# M440 register map
File version: 0.1
Registers are 32-bit, read-write, reset 0x0 unless marked. A register's access mark holds for its fields unless they carry their own. Offsets are from the block's base; [hi:lo] are bit positions; {n}, {i} and the like mark numbered series.

## WD — Watchdog Timer (WD)
Base 0x400F2000
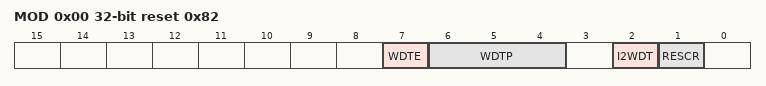
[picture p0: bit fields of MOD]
0x00 MOD reset 0x82 — WD Mode Register
  [7] WDTE, [6:4] WDTP, [2] I2WDT, [1] RESCR
0x04 CR wo (reset mask 0xFFFFFF00) — WD Control Register
  [7:0] WDCR

## CG — Clock Generator (CG)
Base 0x400F3000
0x00 SYSCR reset 0x10000 — System Control Register
  [21] PSCSTOP, [20] FCSTOP2, [18] FCSTOP1, [17] FCSTOP0, [17:16] SCOSEL, [13] FPSEL1 ro, [12] FPSEL0, [10:8] PRCK, [2:0] GEAR
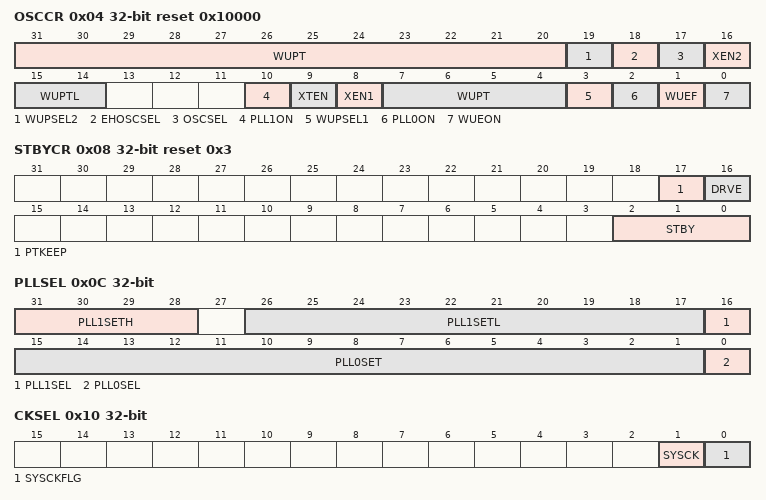
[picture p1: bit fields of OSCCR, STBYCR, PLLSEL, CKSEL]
0x04 OSCCR reset 0x10000 — Oscillation Control Register
  [31:20] WUPT, [19] WUPSEL2, [18] EHOSCSEL, [17] OSCSEL, [16] XEN2, [15:14] WUPTL, [10] PLL1ON, [9] XTEN, [8] XEN1, [7:4] WUPT ro, [3] WUPSEL1, [2] PLL0ON, [1] WUEF ro, [0] WUEON wo
0x08 STBYCR reset 0x3 — Standby Control Register
  [17] PTKEEP, [16] DRVE, [2:0] STBY
0x0C PLLSEL — PLL Selection Register
  [31:28] PLL1SETH, [26:17] PLL1SETL, [16] PLL1SEL, [15:1] PLL0SET, [0] PLL0SEL
0x10 CKSEL — System Clock Selection Register
  [1] SYSCK, [0] SYSCKFLG ro
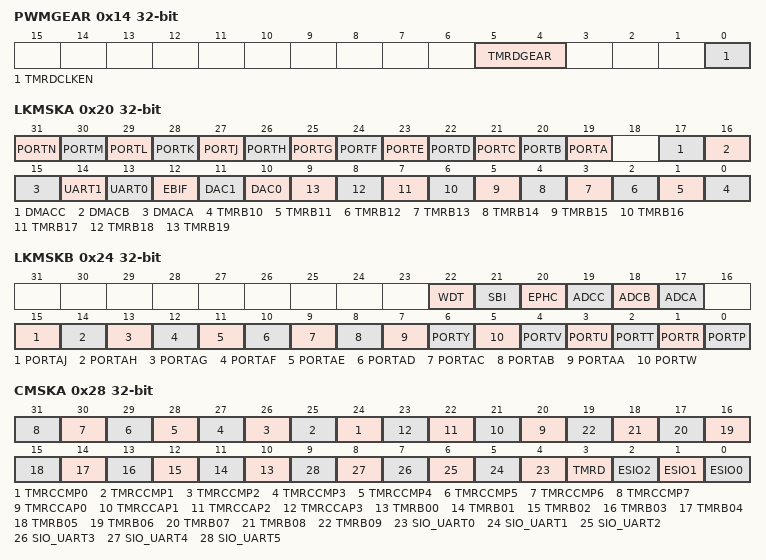
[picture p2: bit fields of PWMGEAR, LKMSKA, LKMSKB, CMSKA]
0x14 PWMGEAR — Timer D Clock Setting Register
  [5:4] TMRDGEAR, [0] TMRDCLKEN
0x20 LKMSKA — fclk Supply Stop Register A
  [31] PORTN, [30] PORTM, [29] PORTL, [28] PORTK, [27] PORTJ, [26] PORTH, [25] PORTG, [24] PORTF, [23] PORTE, [22] PORTD, [21] PORTC, [20] PORTB, [19] PORTA, [17] DMACC, [16] DMACB, [15] DMACA, [14] UART1, [13] UART0, [12] EBIF, [11] DAC1, [10] DAC0, [n-10] TMRB{n} (n=10..19)
0x24 LKMSKB — fclk Supply Stop Register B
  [22] WDT, [21] SBI, [20] EPHC, [19] ADCC, [18] ADCB, [17] ADCA, [15] PORTAJ, [14] PORTAH, [13] PORTAG, [12] PORTAF, [11] PORTAE, [10] PORTAD, [9] PORTAC, [8] PORTAB, [7] PORTAA, [6] PORTY, [5] PORTW, [4] PORTV, [3] PORTU, [2] PORTT, [1] PORTR, [0] PORTP
0x28 CMSKA — fc Supply Stop Register A
  [n+24] TMRCCMP{n} (n=0..7), [n+20] TMRCCAP{n} (n=0..3), [n+10] TMRB{n:02} (n=0..9), [n+4] SIO_UART{n} (n=0..5), [3] TMRD, [2] ESIO2, [1] ESIO1, [0] ESIO0
0x2C CMSKB — fc Supply Stop Register B
  [0] TMRCTBT
0x3C PROTECT reset 0xC1
  [7:0] CGPROTECT
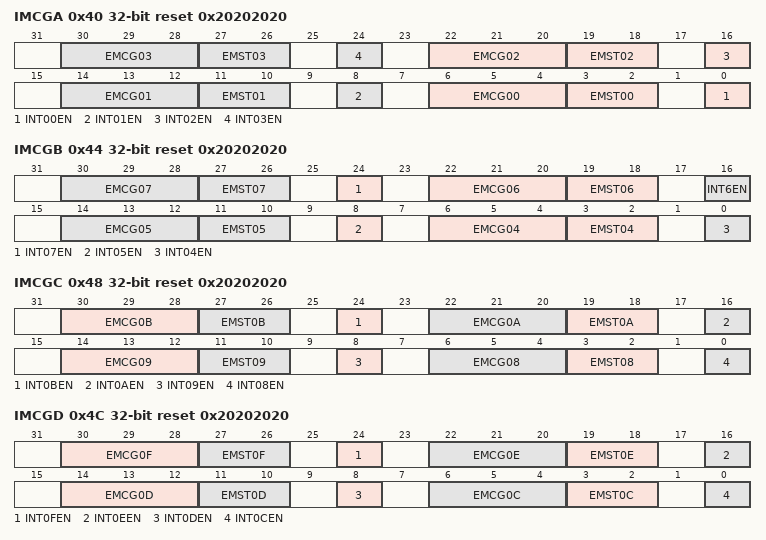
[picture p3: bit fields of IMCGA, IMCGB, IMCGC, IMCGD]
0x40 IMCGA reset 0x20202020 — CG Interrupt Mode Control Register A
  [8n+6:8n+4] EMCG{n:02} (n=0..3), [8n+3:8n+2] EMST{n:02} ro (n=0..3), [8n] INT{n:02}EN (n=0..3)
0x44 IMCGB reset 0x20202020 — CG Interrupt Mode Control Register B
  [8n-26:8n-28] EMCG{n:02} (n=4..7), [8n-29:8n-30] EMST{n:02} ro (n=4..7), [24] INT07EN, [16] INT6EN, [8] INT05EN, [0] INT04EN
0x48 IMCGC reset 0x20202020 — CG Interrupt Mode Control Register C
  [30:28] EMCG0B, [27:26] EMST0B ro, [24] INT0BEN, [22:20] EMCG0A, [19:18] EMST0A ro, [16] INT0AEN, [14:12] EMCG09, [11:10] EMST09 ro, [8] INT09EN, [6:4] EMCG08, [3:2] EMST08 ro, [0] INT08EN
0x4C IMCGD reset 0x20202020 — CG Interrupt Mode Control Register D
  [30:28] EMCG0F, [27:26] EMST0F ro, [24] INT0FEN, [22:20] EMCG0E, [19:18] EMST0E ro, [16] INT0EEN, [14:12] EMCG0D, [11:10] EMST0D ro, [8] INT0DEN, [6:4] EMCG0C, [3:2] EMST0C ro, [0] INT0CEN
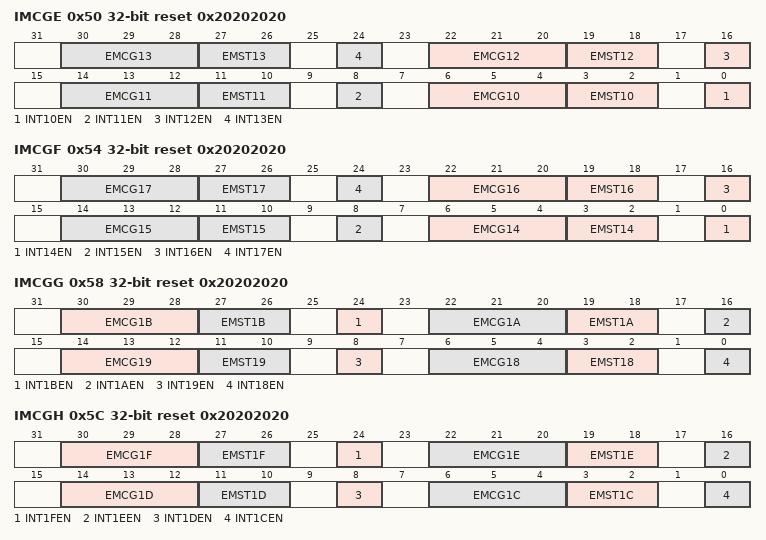
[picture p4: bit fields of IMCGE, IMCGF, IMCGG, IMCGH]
0x50 IMCGE reset 0x20202020 — CG Interrupt Mode Control Register E
  [8n-74:8n-76] EMCG{n} (n=10..13), [8n-77:8n-78] EMST{n} ro (n=10..13), [8n-80] INT{n}EN (n=10..13)
0x54 IMCGF reset 0x20202020 — CG Interrupt Mode Control Register F
  [8n-106:8n-108] EMCG{n} (n=14..17), [8n-109:8n-110] EMST{n} ro (n=14..17), [8n-112] INT{n}EN (n=14..17)
0x58 IMCGG reset 0x20202020 — CG Interrupt Mode Control Register G
  [30:28] EMCG1B, [27:26] EMST1B ro, [24] INT1BEN, [22:20] EMCG1A, [19:18] EMST1A ro, [16] INT1AEN, [14:12] EMCG19, [11:10] EMST19 ro, [8] INT19EN, [6:4] EMCG18, [3:2] EMST18 ro, [0] INT18EN
0x5C IMCGH reset 0x20202020 — CG Interrupt Mode Control Register H
  [30:28] EMCG1F, [27:26] EMST1F ro, [24] INT1FEN, [22:20] EMCG1E, [19:18] EMST1E ro, [16] INT1EEN, [14:12] EMCG1D, [11:10] EMST1D ro, [8] INT1DEN, [6:4] EMCG1C, [3:2] EMST1C ro, [0] INT1CEN
0x60 ICRCG wo — CG Interrupt Request Clear Register
  [4:0] ICRCG
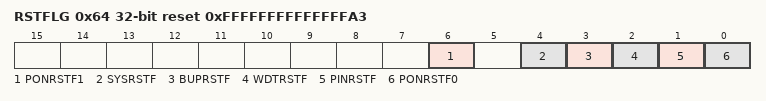
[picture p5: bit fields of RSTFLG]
0x64 RSTFLG reset 0xFFFFFFFFFFFFFFA3 — Reset Flag Register
  [6] PONRSTF1 ro, [4] SYSRSTF, [3] BUPRSTF, [2] WDTRSTF, [1] PINRSTF, [0] PONRSTF0

## KS — Key Matrix Scan
Base 0x400FA000
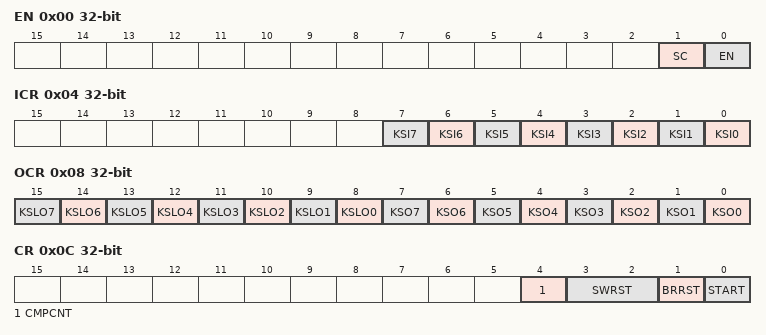
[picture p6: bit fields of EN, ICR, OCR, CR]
0x00 EN — Enable Register
  [1] SC, [0] EN
0x04 ICR — Key Input Control Register
  [n] KSI{n} (n=0..7)
0x08 OCR — Key Output Control Register
  [n+8] KSLO{n} (n=0..7), [n] KSO{n} (n=0..7)
0x0C CR — Control Register
  [4] CMPCNT, [3:2] SWRST, [1] BRRST wo, [0] START
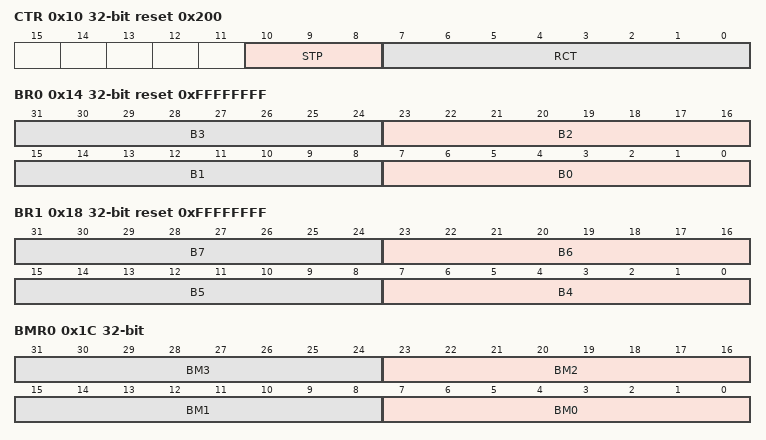
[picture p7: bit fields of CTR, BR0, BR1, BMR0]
0x10 CTR reset 0x200 — Count Register
  [10:8] STP, [7:0] RCT
0x14 BR0 ro reset 0xFFFFFFFF — Buffer0 Register
  [8n+7:8n] B{n} (n=0..3)
0x18 BR1 ro reset 0xFFFFFFFF — Buffer1 Register
  [8n-25:8n-32] B{n} (n=4..7)
0x1C BMR0 — Buffer0 Mask Register
  [8n+7:8n] BM{n} (n=0..3)
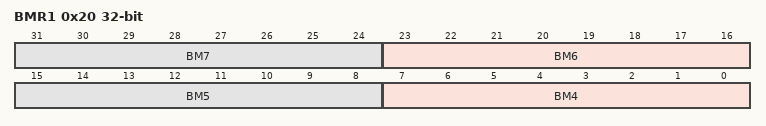
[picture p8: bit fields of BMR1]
0x20 BMR1 — Buffer1 Mask Register
  [8n-25:8n-32] BM{n} (n=4..7)
0x24 INTCR — Interrupt Control Register
  [0] INTEN

## KWUPA — Key On Wake Up
Base 0x400FB000
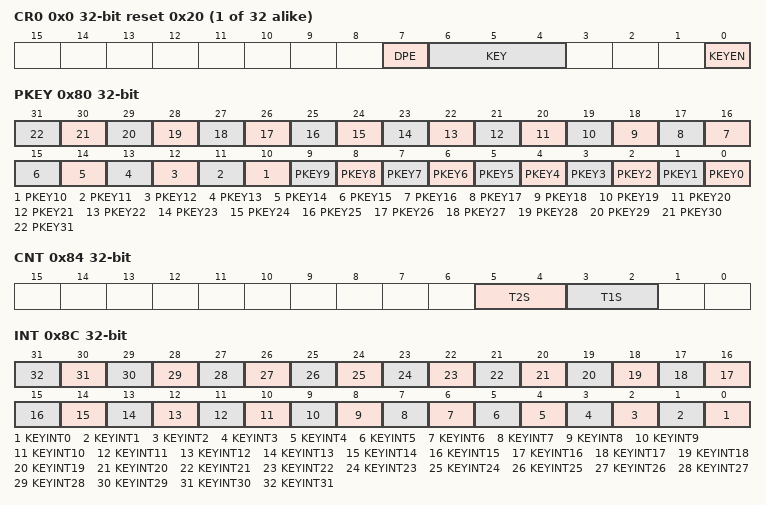
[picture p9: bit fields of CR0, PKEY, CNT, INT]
{0x0+4i} CR{i} reset 0x20 (i=0..31) — Control Register {i}
  [7] DPE, [6:4] KEY, [0] KEYEN
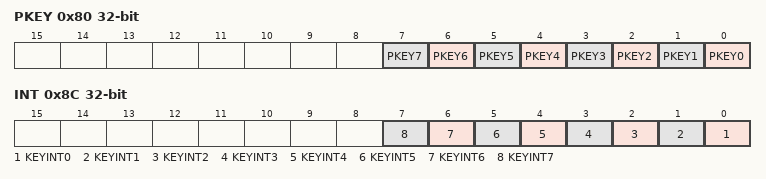
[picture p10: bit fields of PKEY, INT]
0x80 PKEY ro — Port Monitor Register
  [n] PKEY{n} (n=0..31)
0x84 CNT — Control Register
  [5:4] T2S, [3:2] T1S
0x88 CLR wo — Interrupt All Clear Register
  [3:0] KEYCLR
0x8C INT ro — Interrupt Monitor Register
  [n] KEYINT{n} (n=0..31)

## KWUPB — Key On Wake Up
Base 0x400FB100
Registers as KWUPA, without CR{n} (n=8..31); these are added or differ:
0x80 PKEY ro — Port Monitor Register
  [n] PKEY{n} (n=0..7)
0x8C INT ro — Interrupt Monitor Register
  [n] KEYINT{n} (n=0..7)

## FC — Flash Control (FC)
Base 0x41FFF000
0x10 SECBIT reset 0x1 — Security Bit Register
  [0] SECBIT
0x1C CR — Control Register
  [0] FLBOFF
0x20 SR ro reset 0x1 — Flash Status Register
  [0] RDY_BSY
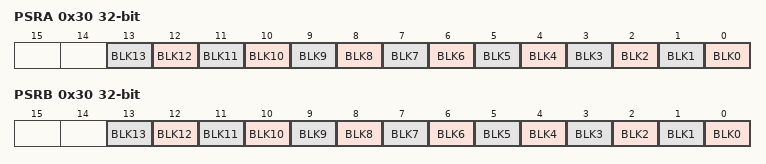
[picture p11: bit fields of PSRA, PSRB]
0x30 PSRA ro (reset mask 0xFFFFC000) — Flash Protect Status Register A
  [n] BLK{n} (n=0..13)
0x30 PSRB ro (reset mask 0xFFFFC000) — Flash Protect Status Register B
  [n] BLK{n} (n=0..13)
